VERSION "1.0"

NS_ :

BS_:

BU_: ECU1_Sensor ECU2_Actuator ECU3_Gateway

VAL_TABLE_ AEB_State 1 "AEB_ACTIVE" 0 "NORMAL" ;
VAL_TABLE_ Button_Mask 3 "ARMED_AND_REVERSE" 2 "ARMED_ONLY" 1 "REVERSE_ONLY" 0 "NO_ACTION" ;

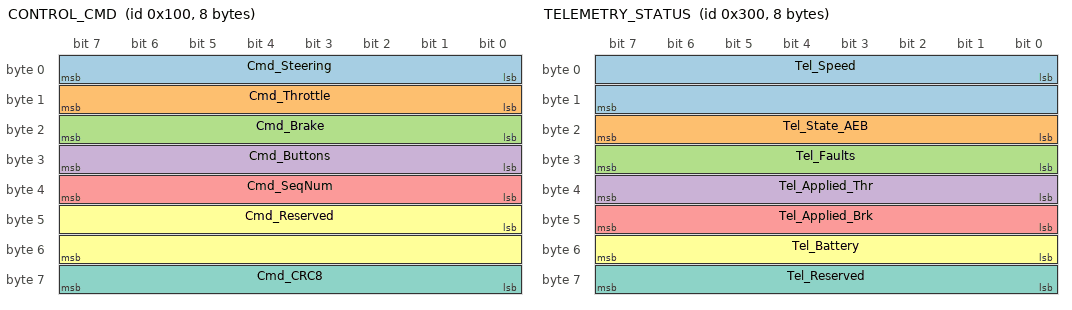
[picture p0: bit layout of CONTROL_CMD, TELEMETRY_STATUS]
BO_ 256 CONTROL_CMD: 8 ECU3_Gateway
 SG_ Cmd_Steering : 0|8@1- (1,0) [-100|100] "%" ECU2_Actuator
 SG_ Cmd_Throttle : 8|8@1+ (1,0) [0|100] "%" ECU2_Actuator
 SG_ Cmd_Brake : 16|8@1+ (1,0) [0|100] "%" ECU2_Actuator
 SG_ Cmd_Buttons : 24|8@1+ (1,0) [0|255] "" ECU2_Actuator
 SG_ Cmd_SeqNum : 32|8@1+ (1,0) [0|255] "Count" ECU2_Actuator
 SG_ Cmd_Reserved : 40|16@1+ (1,0) [0|65535] "-" ECU2_Actuator
 SG_ Cmd_CRC8 : 56|8@1+ (1,0) [0|255] "Hex" ECU2_Actuator

BO_ 512 SENSOR_DISTANCE: 8 ECU1_Sensor
 SG_ Sns_Distance_mm : 0|16@1+ (1,0) [0|65535] "mm" ECU2_Actuator,ECU3_Gateway
 SG_ Sns_Reserved : 16|48@1+ (1,0) [0|0] "-" ECU2_Actuator,ECU3_Gateway

BO_ 768 TELEMETRY_STATUS: 8 ECU2_Actuator
 SG_ Tel_Speed : 0|16@1- (1,0) [-32768|32767] "RPM" ECU3_Gateway
 SG_ Tel_State_AEB : 16|8@1+ (1,0) [0|255] "" ECU3_Gateway
 SG_ Tel_Faults : 24|8@1+ (1,0) [0|255] "Bitmask" ECU3_Gateway
 SG_ Tel_Applied_Thr : 32|8@1+ (1,0) [0|100] "%" ECU3_Gateway
 SG_ Tel_Applied_Brk : 40|8@1+ (1,0) [0|100] "%" ECU3_Gateway
 SG_ Tel_Battery : 48|8@1+ (1,0) [0|100] "%" ECU3_Gateway
 SG_ Tel_Reserved : 56|8@1+ (1,0) [0|0] "-" ECU3_Gateway

BA_DEF_ BO_ "GenMsgCycleTime" INT 0 65535;
BA_DEF_ BO_ "GenMsgSendType" ENUM "Cyclic","NotUsed","NotUsed","NotUsed","NotUsed","Cyclic","NotUsed","IfActive","NoMsgSendType";
BA_DEF_ SG_ "GenSigStartValue" INT 0 65535;
BA_DEF_DEF_ "GenMsgCycleTime" 0;
BA_DEF_DEF_ "GenMsgSendType" "NoMsgSendType";
BA_DEF_DEF_ "GenSigStartValue" 0;

BA_ "GenMsgCycleTime" BO_ 256 20;
BA_ "GenMsgSendType" BO_ 256 0;
BA_ "GenMsgCycleTime" BO_ 512 50;
BA_ "GenMsgSendType" BO_ 512 0;
BA_ "GenMsgCycleTime" BO_ 768 100;
BA_ "GenMsgSendType" BO_ 768 0;

VAL_ 256 Cmd_Buttons 3 "ARMED_AND_REVERSE" 2 "ARMED_ONLY" 1 "REVERSE_ONLY" 0 "NO_ACTION" ;
VAL_ 768 Tel_State_AEB 1 "AEB_ACTIVE" 0 "NORMAL" ;

CM_ BU_ ECU1_Sensor "Sensor node. Measures front obstacle distance and transmits SENSOR_DISTANCE.";
CM_ BU_ ECU2_Actuator "Actuator node. Executes vehicle commands, AEB logic and transmits vehicle telemetry.";
CM_ BU_ ECU3_Gateway "Central gateway. Routes RF commands to CAN and collects CAN telemetry for RF uplink.";

CM_ BO_ 256 "Control command from ECU3 Gateway to ECU2 Actuator. Cyclic period: 20 ms.";
CM_ SG_ 256 Cmd_Steering "Signed steering command. -100 = full left, +100 = full right.";
CM_ SG_ 256 Cmd_Throttle "Requested throttle command, 0 to 100 percent.";
CM_ SG_ 256 Cmd_Brake "Requested brake command. Failsafe state uses 100 percent.";
CM_ SG_ 256 Cmd_Buttons "Bit 0 = Reverse, Bit 1 = Armed.";
CM_ SG_ 256 Cmd_SeqNum "Rolling sequence counter used for duplicate or stale frame detection.";
CM_ SG_ 256 Cmd_Reserved "Reserved for future protocol expansion. Must be zero.";
CM_ SG_ 256 Cmd_CRC8 "Application payload CRC-8. Polynomial 0x07.";

CM_ BO_ 512 "Front obstacle distance measurement from ECU1 Sensor. Cyclic period: 50 ms.";
CM_ SG_ 512 Sns_Distance_mm "Front obstacle distance in millimeters. Valid range: 0 to 65535 mm.";
CM_ SG_ 512 Sns_Reserved "Reserved bytes for future sensor expansion. Must be zero.";

CM_ BO_ 768 "Vehicle telemetry from ECU2 Actuator to ECU3 Gateway. Cyclic period: 100 ms.";
CM_ SG_ 768 Tel_Speed "Actual motor speed. Signed value allows reverse rotation.";
CM_ SG_ 768 Tel_State_AEB "AEB state: 0 = NORMAL, 1 = AEB_ACTIVE.";
CM_ SG_ 768 Tel_Faults "Hardware fault bitmask. Bit allocation is ECU2 application defined.";
CM_ SG_ 768 Tel_Applied_Thr "Actual throttle command applied by the actuator.";
CM_ SG_ 768 Tel_Applied_Brk "Actual brake command applied by the actuator.";
CM_ SG_ 768 Tel_Battery "Battery state of charge in percent. Demonstration value.";
CM_ SG_ 768 Tel_Reserved "Reserved for future telemetry expansion. Must be zero.";
